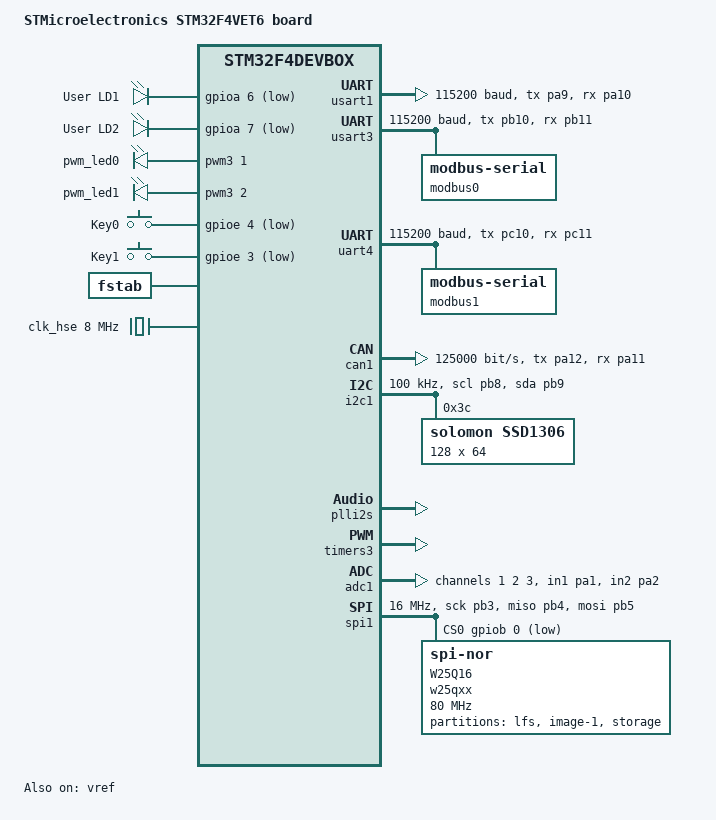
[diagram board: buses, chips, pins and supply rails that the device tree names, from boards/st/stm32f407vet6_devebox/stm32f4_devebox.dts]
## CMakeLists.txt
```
# SPDX-License-Identifier: Apache-2.0

cmake_minimum_required(VERSION 3.20.0)
list(APPEND BOARD_ROOT ${CMAKE_CURRENT_SOURCE_DIR}) # 添加当前目录到BOARD_ROOT
find_package(Zephyr REQUIRED HINTS $ENV{ZEPHYR_BASE})
project(blinky_test)

target_include_directories(app PRIVATE src)
target_include_directories(app PRIVATE src/driver)
target_include_directories(app PRIVATE src/modbus)


target_sources(app PRIVATE src/main.c)

target_sources(app PRIVATE src/driver/adc.c)
target_sources(app PRIVATE src/driver/can_driver.c)
target_sources(app PRIVATE src/driver/fs_storage.c)
target_sources(app PRIVATE src/driver/iic_board.c)
target_sources(app PRIVATE src/driver/modbus_driver.c)
target_sources(app PRIVATE src/driver/uart.c)
target_sources(app PRIVATE src/driver/w25qxx.c)

target_sources(app PRIVATE src/modbus/modbus_ser_a.c)
target_sources(app PRIVATE src/modbus/modbus_cli_a.c)

target_sources(app PRIVATE src/gpio-ctr.c)
target_sources(app PRIVATE src/sys_param.c)
target_sources(app PRIVATE src/oled1306.c)
```

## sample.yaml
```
sample:
  name: Blinky Sample test
tests:
  sample.basic.blinky:
    tags:
      - LED
      - gpio
    filter: dt_enabled_alias_with_parent_compat("led0", "gpio-leds")
    depends_on: gpio
    harness: led
    integration_platforms:
      - frdm_k64f
```

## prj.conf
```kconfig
# =============================================================================
# 调试编译相关配置
# =============================================================================
# CONFIG_DEBUG: 启用调试符号（-g 编译选项）
# 这是所有调试功能的前提，不启用则 GDB 无法映射源码与机器码
CONFIG_DEBUG=y
# 编译优化等级（四选一，互斥）:
#   CONFIG_NO_OPTIMIZATIONS=y   → -O0  零优化，GDB完美调试，代码体积最大
#   CONFIG_DEBUG_OPTIMIZATIONS=y → -Og  调试优化甜点，GDB基本可用，体积比-O0小30-40%
#   （都不设，默认）             → -O2  速度优化，GDB变量常"optimized out"
#   CONFIG_SIZE_OPTIMIZATIONS=y → -Os  体积最小，GDB体验差
# 推荐：日常开发用 -Og（调试与空间的甜点），发布用 -Os
CONFIG_DEBUG_OPTIMIZATIONS=y
# CONFIG_DEBUG_THREAD_INFO: 生成 _kernel_thread_info_offsets 符号
# 原因：OpenOCD 的 Zephyr RTOS 线程感知插件依赖此符号
#       不启用则 OpenOCD 持续报错 "offsets not found"，并可能导致断点失效
#       报错示例："can't find _kernel_thread_info_offsets in symbol table"
CONFIG_DEBUG_THREAD_INFO=y


# =============================================================================
# 线程与日志等配置
# =============================================================================
# CONFIG_THREAD_STACK_INFO: 在线程信息中包含栈指针和栈大小
# GDB/OpenOCD 线程感知需要，用于显示每个线程的栈使用情况
CONFIG_THREAD_STACK_INFO=y
# CONFIG_THREAD_MONITOR: 启用线程监控链表
# OpenOCD 通过遍历内核线程链表枚举所有线程
CONFIG_THREAD_MONITOR=y
# CONFIG_THREAD_NAME: 允许为线程设置名称
# GDB 中显示线程名而非编号，便于识别（如 "main", "idle"）
CONFIG_THREAD_NAME=y

# CONFIG_LOG: 启用 Zephyr 日志子系统
CONFIG_LOG=y
#增大日志缓冲区（默认1024字节，参数系统初始化时日志密集会导致丢消息）
CONFIG_LOG_BUFFER_SIZE=4096

# 启用 Zephyr Shell 子系统
CONFIG_SHELL=y



# =============================================================================
# 修改默认堆栈
# =============================================================================
# 系统工作队列栈大小 (默认 1024)
CONFIG_SYSTEM_WORKQUEUE_STACK_SIZE=4096
#修改主线程栈大小，不开就是默认值
CONFIG_MAIN_STACK_SIZE=4096


# =============================================================================
# MCUboot 配置
# =============================================================================
#启动MCUboot
CONFIG_BOOTLOADER_MCUBOOT=y
# 签名密钥 — 使用 MCUboot 自带的 RSA-2048 默认开发密钥
# 生产环境必须替换为自己的密钥对
CONFIG_MCUBOOT_SIGNATURE_KEY_FILE="bootloader/mcuboot/root-rsa-2048.pem"
# 必须与 MCUboot 的配置保持一致！否则 flash_img 写入偏移与 MCUboot 读取偏移不匹配
# MCUboot 配置了 BOOT_UPGRADE_ONLY=y，APP 也必须使用 OVERWRITE_ONLY 模式
CONFIG_MCUBOOT_BOOTLOADER_MODE_OVERWRITE_ONLY=y

# SPI NOR 页大小等配置已移至 MCUboot 板级配置文件:
#   bootloader/mcuboot/boot/zephyr/boards/stm32f4_devebox.conf
# # Overwrite 模式CONFIG_BOOT_UPGRADE_ONLY=y  Flash 页大小CONFIG_SPI_NOR_FLASH_LAYOUT_PAGE_SIZE=4096
# # 镜像最大扇区数CONFIG_BOOT_MAX_IMG_SECTORS_AUTO=n  CONFIG_BOOT_MAX_IMG_SECTORS=256


# =============================================================================
# MCUmgr DFU 升级配置
# =============================================================================
# MCUmgr 依赖项（Kconfig 不会自动启用，需显式声明）
CONFIG_ZCBOR=y
CONFIG_NET_BUF=y
CONFIG_BASE64=y

# MCUmgr 核心开关
CONFIG_MCUMGR=y
# Image 管理组：提供固件上传、查询、标记升级等命令
CONFIG_MCUMGR_GRP_IMG=y
# DFU 镜像管理器（MCUMGR_GRP_IMG 的依赖，需显式启用）
CONFIG_IMG_MANAGER=y
# OS 管理组：提供远程复位命令（升级后重启进入 MCUboot 执行升级）
CONFIG_MCUMGR_GRP_OS=y
# 流式写入 Flash（MCUmgr 上传固件时需要）
CONFIG_STREAM_FLASH=y
# 允许直接上传到指定 slot（不强制从 slot0 开始）
CONFIG_MCUMGR_GRP_IMG_DIRECT_UPLOAD=y

# Shell 传输：复用现有 Shell 串口进行 SMP 通信
# 优点：无需额外 UART，同一串口同时支持 Shell 命令和 MCUmgr DFU
CONFIG_MCUMGR_TRANSPORT_SHELL=y
# Shell 传输 MTU（默认 256，增大可提升上传速度）
CONFIG_MCUMGR_TRANSPORT_SHELL_MTU=512
# MCUmgr 网络缓冲区大小（默认 384，DFU 场景需增大）
CONFIG_MCUMGR_TRANSPORT_NETBUF_SIZE=2048

# 调试: 启用 MCUMGR 和 stream_flash DEBUG 日志，排查上传失败原因
CONFIG_MCUMGR_LOG_LEVEL_DBG=y
CONFIG_STREAM_FLASH_LOG_LEVEL_DBG=y
CONFIG_IMG_MANAGER_LOG_LEVEL_DBG=y





#GPIO子系统
CONFIG_GPIO=y
#启用输入子系统
CONFIG_INPUT=y
#GPIO按键输入驱动 (gpio-keys compatible 节点的驱动)
#当 DTS 中存在 compatible = "gpio-keys" 节点时，此选项默认启用 (default y)
#显式声明以便于理解配置意图
CONFIG_INPUT_GPIO_KEYS=y
#启用PWM子系统
CONFIG_PWM=y

#启用ADC子系统
CONFIG_ADC=y
#启用ADC调试日志
#CONFIG_ADC_LOG_LEVEL_DBG=y

#启用DMA子系统
CONFIG_DMA=y
# ADC DMA 模式（依赖 DMA 子系统 + DTS 中 ADC 节点已启用）
CONFIG_ADC_STM32_DMA=y
#关闭DMA模块日志输出
#原因：STM32F4 的 DMA V1 驱动对 burst_length 的处理存在语义不匹配——
#  Zephyr API 定义 burst_length 单位为字节，ADC 驱动设置 burst_length=2（16位数据），
#  但 DMA V1 驱动将其当作 beat 数匹配，只接受 {1,4,8,16}，导致每次 ADC DMA 读取时
#  产生 "Peripheral/Memory burst size error" 的 LOG_ERR 误报。
#  实际功能不受影响（驱动自动回退到 single burst），但 ERR 级别日志会污染日志系统。
#排查DMA问题时，可改用 CONFIG_DMA_LOG_LEVEL_ERR 或 CONFIG_DMA_LOG_LEVEL_DBG 重新开启
CONFIG_DMA_LOG_LEVEL_OFF=y

#启用UART子系统
CONFIG_SERIAL=y
#启用UART中断驱动 (uart_irq_rx_enable / uart_irq_callback_set 等 API 的开关)
#不开启的话中断 API 不会被编译进驱动, 中断永不触发
CONFIG_UART_INTERRUPT_DRIVEN=y
#启用UART异步API (uart_tx / uart_rx_enable / uart_callback_set)
#依赖 DMA, 需要 DTS 中配置 dmas 属性
CONFIG_UART_ASYNC_API=y

#启用Modbus子系统
CONFIG_MODBUS=y
#启用Modbus客户端+服务端 (Kconfig choice三选一: CLIENT / SERVER / CLIENT_SERVER)
CONFIG_MODBUS_ROLE_CLIENT_SERVER=y


# 启用 CAN 子系统（CAN 驱动框架核心）
CONFIG_CAN=y
# CAN Shell 命令（调试用，可通过 shell 测试 CAN 收发）
# 命令: can send/can start/can stop/can state 等
CONFIG_CAN_SHELL=y
# CAN 总线状态统计（can_stats_get_bit_errors 等 API 依赖）
# 调试时建议启用，正式发布可关闭
# 需要先启用 STATS 模块
CONFIG_STATS=y
CONFIG_CAN_STATS=y
# CAN 驱动日志级别（调试用，可看到 MCP2515 底层收发日志）
# 正式发布时改为 _WRN 或关闭
# CONFIG_CAN_LOG_LEVEL_DBG=y
CONFIG_CAN_LOG_LEVEL_INF=y


#启用I2C子系统
CONFIG_I2C=y
#启用I2C Shell命令（调试用，可通过shell扫描总线、读写寄存器）
#用法: i2c scan I2C_1          — 扫描总线上所有设备
#      i2c read_byte I2C_1 0x3C 0x00  — 从地址0x3C的设备读寄存器0x00
#CONFIG_I2C_SHELL=y

#启用Display子系统（OLED SSD1306 驱动依赖）
CONFIG_DISPLAY=y
#启用SSD1306驱动（当DTS中存在 compatible="solomon,ssd1306" 节点时默认自动启用）
#显式声明以便于理解配置意图
CONFIG_SSD1306=y




#启用SPI子系统（SPI控制器驱动依赖）
CONFIG_SPI=y
#启用Flash子系统（jedec,spi-nor驱动依赖）
#CONFIG_SPI_NOR 不需要手动开启，当DTS中存在 compatible="jedec,spi-nor" 节点时自动启用
CONFIG_FLASH=y
#启用Flash页面布局信息（flash_get_page_info_by_offs 等API依赖）
CONFIG_FLASH_PAGE_LAYOUT=y
# SPI NOR Flash 页大小（最小擦除单位）
# W25Q16 最小擦除单位是 4KB，必须设置为此值
# 默认值 65536 (64KB) 会导致 MCUboot boot_slots_compatible() 检查失败
# 同时也影响 LittleFS 的块大小选择，4KB 更精确
CONFIG_SPI_NOR_FLASH_LAYOUT_PAGE_SIZE=4096

#启用文件系统子系统（VFS核心层）
CONFIG_FILE_SYSTEM=y
#启用LittleFS文件系统（嵌入式首选，掉电安全+磨损均衡）
CONFIG_FILE_SYSTEM_LITTLEFS=y
#启用Flash Map API（LittleFS通过flash_area读写底层Flash分区）
CONFIG_FLASH_MAP=y
#启用fstab自动挂载（DTS中设置automount的条目在SYS_INIT阶段自动挂载）
CONFIG_FS_LITTLEFS_FSTAB_AUTOMOUNT=y
#启用Flash Shell命令（调试用，可通过shell查看分区和Flash信息）
CONFIG_FLASH_SHELL=y

#启用Settings子系统（参数持久化存储框架）
CONFIG_SETTINGS=y
#使用File后端（基于LittleFS文件系统存储Settings键值对）
CONFIG_SETTINGS_FILE=y
#Settings文件存储路径（必须在已挂载的LittleFS挂载点下）
CONFIG_SETTINGS_FILE_PATH="/lfs1/settings/run"
#Settings文件最大行数（超过后自动压缩去重，减少Flash占用）
CONFIG_SETTINGS_FILE_MAX_LINES=32
```

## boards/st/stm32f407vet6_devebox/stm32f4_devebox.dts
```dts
/*
 * Copyright (c) 2017 Linaro Limited
 *
 * SPDX-License-Identifier: Apache-2.0
 */

/dts-v1/;
#include <st/f4/stm32f407Xg.dtsi>
#include <st/f4/stm32f407v(e-g)tx-pinctrl.dtsi>
#include <zephyr/dt-bindings/input/input-event-codes.h>
#include <zephyr/dt-bindings/dma/stm32_dma.h>

/ {
	model = "STMicroelectronics STM32F4VET6 board";
	compatible = "st,stm32f4devbox";

	/*
	 * chosen 节点: Zephyr 系统的运行时配置参数
	 *
	 * Q: 最少需要指定哪些参数？
	 *
	 * A: 严格来说没有"最少"，但一个能正常启动的 Zephyr 应用至少需要:
	 *    zephyr,sram  — 告诉内核 SRAM 的起始地址和大小（用于内存管理）
	 *    zephyr,flash — 告诉内核 Flash 的起始地址和大小（用于代码定位）
	 *
	 *    zephyr,console  是可选的，但没它就没有串口输出。
	 *    zephyr,shell-uart 也是可选的，只有用 shell 子系统时才需要。
	 *
	 *    常用 chosen 属性一览:
	 *    zephyr,sram        — RAM 节点，内核堆和线程栈从这里分配
	 *    zephyr,flash       — Flash 节点，代码和只读数据存放位置
	 *    zephyr,console     — 默认控制台设备（printk 输出目标）
	 *    zephyr,shell-uart  — Shell 子系统使用的 UART
	 *    zephyr,uart-pipe   — 远程 shell 管道用的 UART
	 *    zephyr,code-partition  — 代码烧录的分区
	 *    zephyr,dtcm / zephyr,itcm — TCM 内存（Cortex-M7 等）
	 */
	chosen {
		zephyr,console = &usart1;
		zephyr,shell-uart = &usart1;
		zephyr,sram = &sram0;
		zephyr,flash = &flash0;
		zephyr,code-partition = &slot0_partition;//指定代码烧录的分区
		zephyr,display = &ssd1306;               //默认显示设备（Display API / LVGL 使用）
	};

	leds {
		compatible = "gpio-leds";

		/*
		 * 设备树节点定义语法:  label: node-name { ... };
		 *
		 *   label     (冒号左边): 节点标签，用于被 & 引用，如 &led0
		 *   node-name (冒号右边): 节点名称，是节点在设备树路径中的名称
		 *
		 * 【易错点】aliases 中 & 引用的是 label，不是 node-name！
		 *
		 *   正确: led0: led_0 { ... };  aliases { led0 = &led0; }
		 *   错误: led0: led_0 { ... };  aliases { led0 = &led_0; }  ← 编译报错！
		 *
		 * 因为 &led_0 试图引用名为 "led_0" 的标签，但标签是 "led0"。
		 * 报错信息: "devicetree error: /aliases: undefined node label 'led_0'"
		 *
		 * 【推荐写法】为避免混淆，建议 label 和 node-name 使用不同命名：
		 *   green_led: led_0 { ... };   aliases { led0 = &green_led; }
		 *   参考 stm32f4_disco 板卡的写法。
		 */
		led0: led_0 {
			gpios = <&gpioa 6 GPIO_ACTIVE_LOW>;
			label = "User LD1";
		};

		led1: led_1 {
			gpios = <&gpioa 7 GPIO_ACTIVE_LOW>;
			label = "User LD2";
		};
	};

	pwmleds: pwmleds {
		compatible = "pwm-leds";

		pwm_led0: pwm_led_0 {
		pwms = <&pwm3 1 PWM_MSEC(20) PWM_POLARITY_NORMAL>;
		/* &pwm3: 引用 timers3 的 pwm 子节点 */
		/* 1: TIM3 通道 1 → PA6 */
		/* PWM_MSEC(20): 周期 20ms = 50Hz，适合 LED 调光 */
		};

		pwm_led1: pwm_led_1 {
		pwms = <&pwm3 2 PWM_MSEC(20) PWM_POLARITY_NORMAL>;
		/* 2: TIM3 通道 2 → PA7 */
		};
	};

	gpio_keys: gpio_keys {
		compatible = "gpio-keys";
		debounce-interval-ms = <30>;    /* 去抖时间 30ms */
		user_button0: button0 {
			label = "Key0";
			gpios = <&gpioe 4 GPIO_ACTIVE_LOW>;
			zephyr,code = <INPUT_KEY_0>;
		};

		user_button1: button1 {
			label = "Key1";
			gpios = <&gpioe 3 GPIO_ACTIVE_LOW>;
			zephyr,code = <INPUT_KEY_1>;
		};

	};

	longpress: longpress {
		compatible = "zephyr,input-longpress";
		input = <&gpio_keys>;                              /* 监听哪个设备，不填则监听所有 */
		input-codes = <INPUT_KEY_0>, <INPUT_KEY_1>;        /* 要检测的按键码 */
		short-codes = <INPUT_KEY_A>, <INPUT_KEY_B>;        /* 短按时输出的码 */
		long-codes = <INPUT_KEY_X>, <INPUT_KEY_Y>;         /* 长按时输出的码 */
		long-delay-ms = <2000>;                             /* 超过此时间算长按 */
	};

	/*
	 * aliases 节点: 为节点创建别名，供 C 代码通过 DT_ALIAS() 宏引用。
	 *
	 * 例如: #define LED0_NODE DT_ALIAS(led0)
	 *       会解析到 aliases 中的 led0 = &led0，进而找到 leds/led_0 节点。
	 *
	 * Zephyr 常用别名约定:
	 *   led0, led1, led2, ...   → LED 指示灯
	 *   sw0, sw1, sw2, ...      → 按键开关
	 *   bt0, bt1, ...           → 按键（另一种命名）
	 *   volt-sensor0, ...       → 电压传感器
	 *   die-temp0, ...          → 芯片温度传感器
	 */
	aliases {
		led0 = &led0;
		led1 = &led1;
		pwm-led0 = &pwm_led0;
		pwm-led1 = &pwm_led1;
		bt0 = &user_button0;
		bt1 = &user_button1;
		adc1 = &adc1;
		volt-sensor0 = &vref;
	};
};


&flash0 {
	partitions {
		compatible = "fixed-partitions";
		#address-cells = <1>;
		#size-cells = <1>;

		/*
		 * STM32F407VET6 内部 flash: 512KB
		 *
		 * 扇区布局（最小擦除单位 = 整个扇区）:
		 * Sector 0: 0x00000000, 16KB
		 * Sector 1: 0x00004000, 16KB
		 * Sector 2: 0x00008000, 16KB
		 * Sector 3: 0x0000C000, 16KB
		 * Sector 4: 0x00010000, 64KB
		 * Sector 5: 0x00020000, 128KB
		 * Sector 6: 0x00040000, 128KB
		 * Sector 7: 0x00060000, 128KB
		 *
		 * MCUboot 分区规划（Overwrite 模式 + 外部 flash slot1）:
		 *   mcuboot  : 48KB   — 引导加载程序（Sector 0~2）
		 *   image-0  : 464KB  — 主应用固件（Sector 3~7）
		 *   image-1  : 512KB  — 升级固件暂存（W25Q16 外部 flash）
		 *
		 * Overwrite 模式说明:
		 *   升级时 MCUboot 从外部 flash 的 slot1 读取镜像，
		 *   覆写到内部 flash 的 slot0，无需 scratch 分区。
		 *   优点: 内部 flash 空间最大化（464KB vs 旧方案 208KB）
		 *   缺点: 升级中断无法回滚（需确保升级过程完整）
		 *   配置: MCUboot 需启用 CONFIG_BOOT_UPGRADE_ONLY=y
		 *
		 * 跨设备 flash 工作原理:
		 *   Zephyr flash_map 为每个分区生成 flash_area 结构体，
		 *   其中 fa_dev 指向对应的 flash 驱动设备:
		 *     slot0 (内部 flash) → fa_dev = SOC_FLASH_STM32 驱动
		 *     slot1 (W25Q16)     → fa_dev = SPI_NOR 驱动
		 *   MCUboot 的 flash_area_read/write/erase 通过 fa_dev
		 *   自动路由到正确的驱动，无需手动区分设备。
		 *
		 *   Overwrite 模式关键路径:
		 *     1. boot_read_image_headers() → flash_area_read(slot1) → SPI NOR 驱动
		 *     2. bootutil_img_validate()   → flash_area_read(slot1) → SPI NOR 驱动
		 *     3. boot_copy_region()        → read(slot1) + write(slot0) → 跨设备复制
		 *     4. do_boot()                 → flash_device_base(slot0) → 内部 flash 跳转
		 *   所有 I/O 操作通过 fa_dev 路由，跳转地址始终是内部 flash。
		 *
		 * 必要配置:
		 *   1. CONFIG_SPI_NOR_FLASH_LAYOUT_PAGE_SIZE=4096
		 *      W25Q16 最小擦除单位是 4KB，必须让驱动报告真实值，
		 *      否则 boot_slots_compatible() 会因 64KB 不能整除 16KB 而失败
		 *   2. CONFIG_BOOT_MAX_IMG_SECTORS=256
		 *      slot1 有 512KB/4KB = 128 个扇区，需增大默认值
		 *
		 * MCUboot 编译命令:
		 *   zephyrproject\bootloader\mcuboot\boot\zephyr> \
		 *   west build -b stm32f4_devebox -d build_mcuboot -- \
		 *     -DCONFIG_BOOT_UPGRADE_ONLY=y
		 *   板级配置文件 boards/stm32f4_devebox.conf 会自动加载
		 */

		boot_partition: partition@0 {
			label = "mcuboot";
			reg = <0x00000000 DT_SIZE_K(48)>;
			read-only;
		};
		slot0_partition: partition@c000 {
			label = "image-0";
			reg = <0x0000C000 DT_SIZE_K(464)>;
		};
	};
};


/*
 * DMA1 必须启用，因为 UART3 和 UART4 的 DMA 请求连接在 DMA1 上：
 *   UART3_TX → DMA1 Stream3 Ch4    UART3_RX → DMA1 Stream1 Ch4
 *   UART4_TX → DMA1 Stream4 Ch4    UART4_RX → DMA1 Stream2 Ch4
 */
&dma1 {
	status = "okay";
};

&dma2 {
	status = "okay";
};

&clk_lsi {
	status = "okay";
};

&clk_hse {
	clock-frequency = <DT_FREQ_M(8)>;
	status = "okay";
};

&pll {
	div-m = <8>;
	mul-n = <336>;
	div-p = <2>;
	div-q = <7>;
	clocks = <&clk_hse>;
	status = "okay";
};

&rcc {
	clocks = <&pll>;
	clock-frequency = <DT_FREQ_M(168)>;
	ahb-prescaler = <1>;
	apb1-prescaler = <4>;
	apb2-prescaler = <2>;
};

&usart1 {
	pinctrl-0 = <&usart1_tx_pa9 &usart1_rx_pa10>;
	pinctrl-names = "default";
	current-speed = <115200>;
	status = "okay";
};

&usart3 {
	pinctrl-0 = <&usart3_tx_pb10 &usart3_rx_pb11>;
	pinctrl-names = "default";
	current-speed = <115200>;
	/*
	 * Async API (DMA 模式) 需要 dmas:
	 *   3 = DMA1 Stream 3 (TX),   4 = Channel 4 (USART3_TX 请求线)
	 *   1 = DMA1 Stream 1 (RX),   4 = Channel 4 (USART3_RX 请求线)
	 *   STM32_DMA_PERIPH_TX = MEM_TO_PERIPH | MEM_INC (默认 8-bit)
	 *   STM32_DMA_PERIPH_RX = PERIPH_TO_MEM | MEM_INC (默认 8-bit)
	 */
	dmas = <&dma1 3 4 STM32_DMA_PERIPH_TX STM32_DMA_FIFO_FULL>,
	       <&dma1 1 4 STM32_DMA_PERIPH_RX STM32_DMA_FIFO_FULL>;
	dma-names = "tx", "rx";
	status = "okay";

	modbus0 {
		compatible = "zephyr,modbus-serial";
		status = "okay";
		/* RS485 收发器需配置 DE 引脚，TTL 直连可省略 */
		/* de-gpios = <&gpiox pin GPIO_ACTIVE_HIGH>; */
	};
};

&uart4 {
	pinctrl-0 = <&uart4_tx_pc10 &uart4_rx_pc11>;
	pinctrl-names = "default";
	current-speed = <115200>;
	/*
	 * UART4 的 DMA 通道:
	 *   4 = DMA1 Stream 4 (TX),   4 = Channel 4 (UART4_TX 请求线)
	 *   2 = DMA1 Stream 2 (RX),   4 = Channel 4 (UART4_RX 请求线)
	 */
	dmas = <&dma1 4 4 STM32_DMA_PERIPH_TX STM32_DMA_FIFO_FULL>,
	       <&dma1 2 4 STM32_DMA_PERIPH_RX STM32_DMA_FIFO_FULL>;
	dma-names = "tx", "rx";
	status = "okay";
	modbus1 {
		compatible = "zephyr,modbus-serial";
		status = "okay";
		/* RS485 收发器需配置 DE 引脚，TTL 直连可省略 */
		/* de-gpios = <&gpiox pin GPIO_ACTIVE_HIGH>; */
	};
};

&can1 {
	pinctrl-0 = <&can1_tx_pa12 &can1_rx_pa11>;
	pinctrl-names = "default";
	bitrate = <125000>;
	sample-point = <875>;
	status = "okay";

	can-transceiver {
		max-bitrate = <1000000>;
	};
};

/*
 * I2C1 节点配置详解
 *
 * Q: pinctrl-0 和 pinctrl-names 是什么？为什么 I2C 必须配置？
 *
 * A: pinctrl (Pin Controller) 是 Zephyr 的引脚复用配置机制。
 *    STM32 的每个引脚可以映射到多种外设功能（AF），必须显式指定。
 *
 *    pinctrl-0: 引用 pinctrl dtsi 中预定义的引脚配置节点
 *    pinctrl-names: 为 pinctrl-0 起个名字，"default" 表示默认（也是唯一）配置
 *
 *    I2C 引脚必须配置的原因:
 *    1. STM32 引脚默认是 GPIO 模式，不配置 pinctrl 则 I2C 信号无法输出到引脚
 *    2. I2C 是开漏协议，必须设置 drive-open-drain（pinctrl dtsi 中已预设）
 *    3. I2C 需要上拉电阻，pinctrl 中已设置 bias-pull-up（内部弱上拉，外部仍需上拉）
 *
 *    PB8 = I2C1_SCL (AF4), PB9 = I2C1_SDA (AF4)
 *    这是 I2C1 的默认引脚，定义在 stm32f407v(e-g)tx-pinctrl.dtsi 中
 *
 * Q: clock-frequency 的选择？
 *
 * A: I2C 标准定义了三种速率:
 *    I2C_BITRATE_STANDARD = 100 KHz  (标准模式, 默认值, 兼容性最好)
 *    I2C_BITRATE_FAST     = 400 KHz  (快速模式, 大多数传感器支持)
 *    I2C_BITRATE_FAST_PLUS = 1 MHz   (高速模式, 部分设备支持)
 *
 *    注意: 速率越高，信号完整性要求越高，线长越短。
 *    面包板/杜邦线建议用 100KHz，PCB 短线可用 400KHz。
 *
 * Q: 总线上的设备子节点怎么写？
 *
 * A: I2C 总线设备子节点格式:
 *    device_name: device@address {
 *        compatible = "vendor,device";   // 匹配驱动
 *        reg = <address>;               // 7位地址（不含R/W位）
 *        label = "Friendly Name";       // 旧式标签（可选）
 *    };
 *
 *    address 是 7 位地址（0x00~0x7F），不含最低位的 R/W 标志。
 *    例如: 0x78 = 0b01111000，这是 7 位地址 0x3C 左移 1 位的结果
 *    如果设备数据手册写的是 8 位地址 0x78，则 7 位地址 = 0x78 >> 1 = 0x3C
 *
 *    【重要】0x78 的两种解读:
 *    - 如果 0x78 是 8 位写地址（最常见）: 7 位地址 = 0x78 >> 1 = 0x3C
 *    - 如果 0x78 已经是 7 位地址（少见）: reg = <0x78>
 *    大多数 I2C 设备数据手册给出的地址是包含 R/W 位的 8 位格式，
 *    OLED SSD1306 的常见地址就是 0x3C（7位）或 0x78（8位写）。
 */
&i2c1 {
	pinctrl-0 = <&i2c1_scl_pb8 &i2c1_sda_pb9>;
	pinctrl-names = "default";
	clock-frequency = <I2C_BITRATE_STANDARD>;
	status = "okay";

	/*
	 * SSD1306 OLED 显示屏 (128x64, I2C)
	 *
	 * compatible: "solomon,ssd1306" — 匹配 Zephyr 内置的 SSD1306 驱动
	 *   驱动源码: zephyr/drivers/display/display_ssd1306.c
	 *   DTS绑定: zephyr/dts/bindings/display/solomon,ssd1306-common.yaml
	 *
	 * 属性说明:
	 *   reg              — 7 位 I2C 地址 (0x3C = 8位地址 0x78 >> 1)
	 *   width/height     — 显示分辨率（像素）
	 *   segment-offset   — 列起始偏移（Page 寻址模式下，0 表示从第 0 列开始）
	 *   page-offset      — 页起始偏移（0 表示从第 0 页开始）
	 *   display-offset   — 显示 RAM 到屏幕的行偏移（0 表示无偏移）
	 *   multiplex-ratio  — 复用比 = height - 1（128x64 → 63, 128x32 → 31）
	 *   prechargep       — 预充电周期 [高位:Phase2 低位:Phase1]，0x22 为典型值
	 *   segment-remap    — 水平镜像（列地址 127 映射到 SEG0）
	 *   com-invdir       — 垂直镜像（COM 扫描方向从 COM63 到 COM0）
	 *
	 * segment-remap + com-invdir 的组合效果:
	 *   都不设: 正常方向（适合大多数模块的默认方向）
	 *   都设置: 旋转 180°（如果显示内容上下颠倒，加这两个属性）
	 *   只设一个: 水平或垂直镜像
	 *
	 * reset-gpios: 可选，硬件 RESET 引脚。如果你的模块没有连接 RESET 引脚
	 *   （很多廉价模块直接把 RESET 拉高），可以省略此属性。
	 *   驱动会使用软件复位命令代替。
	 *
	 * SSD1315 兼容性说明:
	 *   SSD1315 是 SSD1306 的国产替代芯片，指令集高度兼容。
	 *   大多数情况下 "solomon,ssd1306" 驱动可以直接驱动 SSD1315。
	 *   如果显示异常，可能需要调整 prechargep 或对比度参数。
	 */
	ssd1306: ssd1306@3c {
		compatible = "solomon,ssd1306";
		reg = <0x3c>;
		width = <128>;
		height = <64>;
		segment-offset = <0>;
		page-offset = <0>;
		display-offset = <0>;
		multiplex-ratio = <63>;
		prechargep = <0x22>;
		segment-remap;
		com-invdir;
	};

	/*
	 * 通用 I2C 设备节点（保留用于 I2C 底层学习）
	 *
	 * 这个节点使用 "zephyr,i2c-device" 通用 compatible，不绑定任何专用驱动。
	 * iic_board.c 中的 i2c_board_scan()、i2c_board_write_reg() 等底层 API
	 * 使用此节点的地址进行 I2C 总线操作练习。
	 *
	 * 注意: SSD1306 和此节点共享同一个 I2C 地址 0x3C，它们是同一个物理设备。
	 *   - 使用 Zephyr Display API 操作屏幕时，通过 ssd1306 节点
	 *   - 学习 I2C 底层通信时，通过此节点（i2c_board_test 等）
	 *   两者不要同时操作，否则可能产生总线冲突。
	 */
	i2c_device_0x78: i2cdev@3c {
		compatible = "zephyr,i2c-device";
		reg = <0x3C>;
		label = "I2C_DEV_0x78";
		/*
		 * 默认禁用: 与 ssd1306 节点共享同一 I2C 地址 0x3C。
		 * 启用 SSD1306 驱动时，两个节点同时 enabled 会导致驱动冲突。
		 * 使用 iic_board 底层测试时，需要:
		 *   1. 将此节点改为 status = "okay"
		 *   2. 将 ssd1306 节点改为 status = "disabled"
		 *   3. 重新编译
		 */
		status = "disabled";
	};
};

/*
 * &vref: 内部参考电压（VREFINT）监测器
 *
 * Q: 这个是什么？一定需要 okay 吗？
 *
 * A: vref 是 STM32 芯片内部的一个校准电压通道（ADC1 通道 17），
 *    电压约 1.21V 且非常稳定。它不是外部引脚，而是芯片内部连接到
 *    ADC 的专用信号。
 *
 *    用途:
 *    1. adc_raw_to_millivolts() 内部用 vref 的值来计算实际 VDDA
 *       因为 VDDA 不一定是精确的 3.3V（可能是 3.2~3.4V），通过
 *       测量稳定的 VREFINT 可以反推真实的 VDDA 电压。
 *
 *       VDDA_real = VREFINT_cal / VREFINT_measured × VDDA_cal
 *       (VREFINT_cal 出厂时校准值存储在 Flash OTP 区域)
 *
 *    2. 如果不启用 vref，adc_raw_to_millivolts() 假定 VDDA = 3.3V
 *       精度会下降，但对于学习项目差异不大。
 *
 *    结论: 学习阶段不启用也可以（status = "disabled"），
 *          但启用后 ADC 电压转换更精确。
 */
&vref {
	status = "okay";
};


&plli2s {
	/* Minimize audio clock error (with i2s mck-enabled) for all of:
	 * - 22.05kHz / 16b, 24b or 32b
	 * - 44.1kHz  / 16b, 24b or 32b
	 * - 88.2kHz  / 16b or 24b
	 * Note: because the PLLI2S is dependent on the main PLL, the latter
	 *       should not be changed without checking impact on PLLI2S
	 */
	div-m = <8>;
	mul-n = <271>;
	div-r = <2>;
	clocks = <&clk_hse>;
	status = "okay";
};

&timers3 {
    status = "okay";
    st,prescaler = <83>;

    pwm3: pwm {
        status = "okay";
        pinctrl-0 = <&tim3_ch1_pa6 &tim3_ch2_pa7>;
        pinctrl-names = "default";
    };
};

/*
 * ============================================================================
 * ADC1 节点配置详解
 * ============================================================================
 *
 * Q: #address-cells = <1>  这是什么？为什么是 1？
 *
 * A: #address-cells 指定子节点 reg 属性中"地址"部分占用的 cell 数量。
 *    一个 cell 是 32 位整数。
 *
 *    #address-cells = <1> 意味着子节点的 reg = <地址>，只占 1 个 cell。
 *    例如: channel@1 { reg = <1>; }  — 1 cell 的地址
 *
 *    如果是 #address-cells = <2>，则需要 2 个 cell:
 *        somechild@1000,2000 { reg = <0x1000 0x2000>; }
 *
 *    常见值:
 *    <1> 用于简单索引地址（通道号、端口号等）
 *    <2> 用于 64 位地址（如 32 位处理器的 64 位外设地址）
 *
 * Q: #size-cells = <0>  这是什么？为什么是 0？
 *
 * A: #size-cells 指定子节点 reg 属性中"大小"部分占用的 cell 数量。
 *
 *    #size-cells = <0> 意味着子节点的 reg 只有"地址"没有"大小"。
 *    channel@1 { reg = <1>; }     — 只有地址 1，无大小
 *
 *    #size-cells = <1>:
 *    somenode@40000000 { reg = <0x40000000 0x400>; }  — 地址 + 大小
 *
 *    对于 ADC 通道，通道号 (1, 2, ...) 本身就是地址，没有"大小"概念，
 *    所以 #size-cells = <0>。
 *
 * Q: dmas = <&dma2 0 0 (STM32_DMA_PERIPH_RX | STM32_DMA_16BITS) STM32_DMA_FIFO_FULL>;
 *    定义了 dmas 可以不使用 dma 吗？参数什么含义？
 *
 * A: 可以！dmas 只是声明"我可以用 DMA"，是否实际启用取决于:
 *    - Kconfig: CONFIG_DMA=y 且 CONFIG_ADC_STM32_DMA=y
 *    - DTS: dma 控制器本身 status = "okay"
 *    如果 Kconfig 没开，dmas 属性被编译进 DT 但驱动不会初始化 DMA。
 *
 *    4 个 cell 参数的含义 (st,stm32-dma-v1 的 #dma-cells = <4>):
 *
 *    Cell 0 (channel): 0  — DMA2 的流编号 (Stream 0)
 *         STM32F4 有 2 个 DMA 控制器，每个 8 个 Stream (0~7)。
 *         ADC1 可以使用 DMA2 Stream 0 或 Stream 4，这里选 Stream 0。
 *
 *    Cell 1 (slot):    0  — DMA 请求通道号 (Channel 0)
 *         每个外设在 DMA 控制器上有一个固定的请求通道。
 *         STM32F407 中 ADC1 的 DMA 请求连接到 DMA2 Channel 0。
 *
 *    Cell 2 (channel_config): (STM32_DMA_PERIPH_RX | STM32_DMA_16BITS)
 *         STM32_DMA_PERIPH_RX = PERIPH_TO_MEMORY(方向:外设→内存) | MEM_INC(内存地址递增)
 *         STM32_DMA_16BITS    = PERIPH_16BITS(外设数据16位宽) | MEM_16BITS(内存数据16位宽)
 *         两者按位或组合成完整的通道配置位域。
 *
 *    Cell 3 (features): STM32_DMA_FIFO_FULL — FIFO 阈值全满
 *         FIFO_THRESHOLD_1_4 = 0  (1/4 满触发传输)
 *         FIFO_THRESHOLD_HALF = 1 (半满触发传输)
 *         FIFO_THRESHOLD_3_4  = 2 (3/4 满触发传输)
 *         FIFO_THRESHOLD_FULL = 3 (全满触发传输)
 *         对于 ADC DMA，这个值影响不大，驱动会自动处理。
 *
 * Q: channel@1 中四个参数什么意思？和 adc.c 重复吗？
 *
 * A: DTS 中的属性声明硬件默认值，C 代码中的 adc_channel_cfg 是运行时配置。
 *
 *    两者关系:
 *    DTS channel@1 定义了:
 *      reg                     — 通道号 (1 = ADC_IN1)
 *      zephyr,gain             — 默认增益
 *      zephyr,reference        — 默认参考源
 *      zephyr,acquisition-time — 默认采样时间
 *      zephyr,resolution       — 默认分辨率
 *
 *    C 代码 adc_channel_setup() 时:
 *      驱动先读取 DTS 的默认值，然后用 adc_channel_cfg 中的值覆盖。
 *      如果 adc_channel_cfg 某字段未设置(值为 0)，则沿用 DTS 默认值。
 *
 *    所以 DTS 是"出厂默认值"，C 代码是"运行时覆盖"。
 *    两者都写是为了: DTS 让硬件配置可见 + C 代码显式控制。
 *    简单场景下只写 adc_channel_cfg 也能工作（驱动会用默认值填充）。
 */
&adc1 {
	#address-cells = <1>;
	#size-cells = <0>;

	pinctrl-0 = <&adc1_in1_pa1 &adc1_in2_pa2>;
	pinctrl-names = "default";
	st,adc-prescaler = <4>;
	dmas = <&dma2 0 0 (STM32_DMA_PERIPH_RX | STM32_DMA_16BITS) STM32_DMA_FIFO_FULL>;
	status = "okay";

	channel@1 {
		reg = <1>;
		zephyr,gain = "ADC_GAIN_1";
		zephyr,reference = "ADC_REF_INTERNAL";
		zephyr,acquisition-time = <ADC_ACQ_TIME_DEFAULT>;
		zephyr,resolution = <12>;
	};

	channel@2 {
		reg = <2>;
		zephyr,gain = "ADC_GAIN_1";
		zephyr,reference = "ADC_REF_INTERNAL";
		zephyr,acquisition-time = <ADC_ACQ_TIME_DEFAULT>;
		zephyr,resolution = <12>;
	};

	channel@16 {
		reg = <3>;
		zephyr,gain = "ADC_GAIN_1";
		zephyr,reference = "ADC_REF_INTERNAL";
		zephyr,acquisition-time = <ADC_ACQ_TIME_DEFAULT>;
		zephyr,resolution = <12>;
	};
};

&spi1 {
	status = "okay";
	pinctrl-0 = <&spi1_sck_pb3 &spi1_miso_pb4 &spi1_mosi_pb5>;
	pinctrl-names = "default";
	/* SPI1 外设时钟频率（APB2 经分频后的输入时钟） */
	clock-frequency = <16000000>;
	/*
	 * CS 片选 GPIO 列表：
	 *   子节点 reg=<0> 对应此列表的第 0 项，reg=<1> 对应第 1 项，以此类推
	 *   GPIO_ACTIVE_LOW 表示 CS 低电平有效（W25Q16 的 /CS 引脚）
	 *   如果硬件上 CS 直接连 GND（始终选中），jedec,spi-nor 驱动将无法正常工作，
	 *   因为驱动需要在每次 SPI 事务之间拉高 CS 来分隔命令帧
	 */
	cs-gpios = <&gpiob 0 GPIO_ACTIVE_LOW>;//是数组来的

	w25qxx: w25qxx@0 {
		compatible = "jedec,spi-nor";
		/* reg=<0> 对应 cs-gpios 列表第 0 项（PB0） */
		reg = <0>;
		/*
		 * SPI 最大时钟频率：
		 *   W25Q16 标准读模式最高 104 MHz，实际取 80 MHz 留余量
		 */
		spi-max-frequency = <80000000>;
		label = "W25Q16";
		/*
		 * JEDEC ID：[制造商 类型 容量]
		 *   ef = Winbond (华邦)
		 *   40 = 内存类型
		 *   15 = 16 Mbit 容量代码
		 * 驱动初始化时会读取芯片的 JEDEC ID 与此值比对校验
		 */
		jedec-id = [ef 40 15];
		/*
		 * Flash 容量，单位为 bit：
		 *   16777216 = 16 Mbit = 2 MB（W25Q16 的 "16" 指 16 Mbit）
		 */
		size = <16777216>;

		/*
		 * W25Q16 分区表（fixed-partitions）：
		 *   将 2MB Flash 划分为多个逻辑分区，每个分区可独立使用
		 *
		 * slot1_partition 在外部 flash 上的工作原理:
		 *   Zephyr flash_map 根据 DTS 自动为每个分区生成 flash_area 结构体，
		 *   fa_dev 字段通过 DT_MTD_FROM_PARTITION() 宏自动解析:
		 *     partition → fixed-partitions → w25qxx (jedec,spi-nor) → SPI NOR 驱动
		 *   因此 slot1 的 fa_dev 指向 W25Q16 的 SPI NOR 驱动，
		 *   MCUboot 通过 flash_area_read(slot1) 即可读取外部 flash 中的升级镜像。
		 *
		 */
		partitions {
			compatible = "fixed-partitions";
			#address-cells = <1>;
			#size-cells = <1>;

			lfs_partition: partition@0 {
				label = "lfs";
				reg = <0x00000000 0x00100000>; /* 前 1MB 给 LittleFS */
			};

			slot1_partition: partition@100000 {
				label = "image-1";
				reg = <0x00100000 0x00074000>; /* 464KB 给 MCUbot slot1 */
			};

			storage_partition: partition@174000 {
				label = "storage";
				reg = <0x00174000 0x0008c000>; /* 后 560KB 预留 */
			};
		};
	};
};

/*
 * 文件系统挂载表（fstab）：
 *   在 DTS 中声明文件系统挂载参数，构建系统自动生成 fs_mount_t 结构体
 *   应用代码通过 FS_FSTAB_DECLARE_ENTRY(DT_NODELABEL(lfs1)) 引用
 *
 * fstab 与传统手动 fs_mount() 的区别：
 *   - fstab：DTS 声明 → 自动生成结构体 → automount 自动挂载，代码零行
 *   - 手动：C 代码声明 fs_mount_t → 手动填充参数 → 手动调用 fs_mount()
 *   fstab 是 Zephyr 4.x 推荐方式，参数与硬件配置集中管理在 DTS 中
 */
/ {
	fstab {
		compatible = "zephyr,fstab";

		lfs1: lfs1 {
			compatible = "zephyr,fstab,littlefs";
			/* 挂载点路径：文件操作时使用此路径前缀，如 "/lfs1/config.txt" */
			mount-point = "/lfs1";
			/* 引用上面定义的 lfs_partition 分区 */
			partition = <&lfs_partition>;
			/*
			 * automount：启动时自动挂载
			 * 如果不设置，需要在应用代码中手动调用 fs_mount()
			 */
			automount;
			/*
			 * LittleFS 参数说明：
			 *   read-size      : 最小读取粒度（字节），建议 ≥ 16
			 *   prog-size      : 最小编程粒度（字节），建议 ≥ 16
			 *   cache-size     : 读/写缓存大小（字节），越大性能越好，但占用更多 RAM
			 *   lookahead-size : 前瞻缓冲区大小（字节），必须是 8 的倍数
			 *   block-cycles   : 磨损均衡擦除周期，0=禁用磨损均衡
			 *                    推荐 256~1024，值越大写入越快但磨损均衡越弱
			 *
			 * 这些参数影响 RAM 占用和性能，W25Q16 (2MB) 的推荐值：
			 *   RAM 占用 ≈ cache-size * 2 + lookahead-size ≈ 64*2+32 = 160 字节
			 */
			read-size = <16>;
			prog-size = <16>;
			cache-size = <64>;
			lookahead-size = <32>;
			block-cycles = <512>;
		};
	};
};
```

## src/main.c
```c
/*
 * Copyright (c) 2016 Intel Corporation
 *
 * SPDX-License-Identifier: Apache-2.0
 */

#include <stdio.h>
#include <inttypes.h>          // 提供 PRIu32 等格式化宏，用于跨平台打印 uint32_t
#include <string.h>
#include <zephyr/kernel.h>


#include "adc.h"
#include "uart.h"
#include "gpio-ctr.h"
#include "can_driver.h"
#include "modbus_driver.h"
#include "modbus_ser_a.h"
#include "modbus_cli_a.h"
#include "w25qxx.h"
#include "fs_storage.h"
#include "sys_param.h"
#include "iic_board.h"
#include "oled1306.h"

/* 初始化板级资源 */
static int board_init(void)
{
	int ret;
	ret = gpio_init_init();
	if (ret < 0) {
		printk("ERR: gpio init failed\n");
		return 1;
	}
	ret = adc_init();
	if (ret < 0) {
		printk("ERR: adc init failed\n");
		return 1;
	}

	/* 初始化文件系统（LittleFS 自动挂载检查） */
	ret = fs_storage_init();
	if (ret < 0) {
		printk("ERR: fs_storage init failed\n");
		return 1;
	}

	/* 运行文件系统读写测试 
	ret = fs_storage_test();
	if (ret < 0) {
		printk("ERR: fs_storage test failed\n");
	}
	*/

	/* 初始化参数系统（依赖 LittleFS 已挂载） */
	ret = sys_param_init();
	if (ret < 0) {
		printk("ERR: sys_param init failed\n");
		return 1;
	}

	/* 运行参数系统测试 
	ret = sys_param_test();
	if (ret < 0) {
		printk("ERR: sys_param test failed\n");
	}
	*/

	ret = can_drv_init_all();
	if (ret < 0) {
		printk("ERR: can_drv_init_all failed\n");
		return 1;
	}

	/* 串口初始化，已经用作modbus通信，这里注释掉
	ret = uart_init();
	if (ret < 0) {
		printk("ERR: uart init failed\n");
		return 1;
	}
	*/

	ret = modbus_ser_a_register();//注册服务器节点
	if (ret < 0) {
		printk("ERR: modbus_ser_a_register failed\n");
		return 1;
	}
	ret = modbus_cli_a_register();//注册客户端节点
	if (ret < 0) {
		printk("ERR: modbus_cli_a_register failed\n");
		return 1;
	}
	ret = modbus_drv_init_all();//初始化所有modbus驱动
	if (ret < 0) {
		printk("ERR: modbus_drv_init_all failed\n");
		return 1;
	}
	
	/* 初始化 W25Q16 SPI NOR Flash 已经用作文件系统，这里注释掉
	ret = w25qxx_init();
	if (ret < 0) {
		printk("ERR: w25qxx init failed\n");
		return 1;
	}
	/* w25qxx_test(); */
	
	/*
	 * 初始化 I2C1 总线
	 */
	ret = i2c_board_test();
	if (ret < 0) {
		printk("WARN: i2c board test failed (%d), continue...\n", ret);
	}

	/*
	 * OLED SSD1306 显示测试
	 */
	ret = oled_test();
	if (ret < 0) {
		printk("WARN: OLED test failed (%d), system continues "
		       "without display\n", ret);
	}

	/*
	 * 【重要】board_init() 必须显式 return 0。
	 *
	 * 在 ARM Cortex-M (GCC) 上，返回 int 的函数如果缺少 return 语句，
	 * R0 寄存器会残留上次函数调用的结果，导致 main() 收到一个随机的
	 * 返回值。例如当 oled_test() 返回 -19 (-ENODEV) 时，-19 会留在 R0
	 * 中被 main() 误判为 board_init() 失败，执行 return 1 使系统空闲。
	 */
	return 0;
}

/* ========================================================================== *
 * LED 控制线程                                                                *
 *                                                                            *
 * Zephyr 线程创建三要素：                                                     *
 *   1. 线程栈空间 — 必须通过 K_THREAD_STACK_DEFINE 宏静态分配，保证对齐要求    *
 *   2. 线程结构体 — struct k_thread，内核用于管理线程的内部对象                 *
 *   3. 线程入口函数 — 签名必须为 void func(void *p1, void *p2, void *p3)      *
 *                                                                            *
 * 线程优先级说明（数值越小优先级越高）：                                        *
 *   - 0 为最高优先级（仅限零延迟中断处理），一般应用不应使用                     *
 *   - 1~7 为协作式线程优先级，除非主动让出 CPU（k_yield/k_sleep），否则不会被打断 *
 *   - 8~14 为抢占式线程优先级，调度器会按优先级抢占调度                         *
 *   - 15 为最低优先级（idle 线程），一般不使用                                  *
 *   本线程优先级设为 5（协作式），LED 控制无需实时抢占，主动 sleep 让出 CPU 即可 *
 * ========================================================================== */

/* 线程栈大小（字节）
 * LED 控制逻辑简单，无大数组或深层调用栈，1024 字节足够
 * 可通过 k_thread_stack_space_get() 运行时查看剩余栈空间
 */
#define LED_THREAD_STACK_SIZE 1024
/* 线程优先级：5（协作式，不会抢占其他协作式线程） */
#define LED_THREAD_PRIORITY   5
/* 静态分配线程栈
 * K_THREAD_STACK_DEFINE 会处理 Zephyr 要求的栈对齐（通常 32 字节对齐）
 * 不能用普通数组代替，否则可能导致栈溢出或对齐异常
 */
K_THREAD_STACK_DEFINE(led_thread_stack, LED_THREAD_STACK_SIZE);
/* 线程结构体 — 内核通过此结构体管理线程状态、优先级、栈指针等 */
static struct k_thread led_thread_data;
/* 线程入口函数
 * Zephyr 线程入口函数固定签名为 void func(void *p1, void *p2, void *p3)
 * 三个 void* 参数通过 k_thread_create() 的 p1/p2/p3 传入
 * 本线程不需要参数，用 ARG_UNUSED 消除编译器未使用警告
 */
static void led_thread_entry(void *p1, void *p2, void *p3)
{
	ARG_UNUSED(p1);
	ARG_UNUSED(p2);
	ARG_UNUSED(p3);

	while (1) {
		led_ctr_ser();
		k_msleep(1); /* 休眠 1ms，主动让出 CPU，允许其他线程运行 */
	}
}

int main(void)
{
	int ret;
	static int cnt = 0;
	static int uart_cnt = 0;
	static uint8_t rec_can_flag = 0;
	char uart_msg[128];

	ret = board_init();
	if (ret < 0) {
		printk("ERR: board init failed\n");
		return 1;
	}

	
	modbus_cli_a_start();//启动客户端节点

	/* 启动 LED 控制线程
	 *
	 * k_thread_create 参数说明：
	 *   参数1 &led_thread_data  — 线程结构体指针，内核用此管理线程
	 *   参数2 led_thread_stack  — 线程栈起始地址（K_THREAD_STACK_DEFINE 分配）
	 *   参数3 K_THREAD_STACK_SIZEOF(led_thread_stack) — 栈大小
	 *          注意：必须用 K_THREAD_STACK_SIZEOF 宏而非 LED_THREAD_STACK_SIZE，
	 *          因为 K_THREAD_STACK_DEFINE 可能因对齐而多分配空间
	 *   参数4 led_thread_entry  — 线程入口函数
	 *   参数5/6/7 NULL, NULL, NULL — 传给入口函数的 p1/p2/p3 参数
	 *   参数8 LED_THREAD_PRIORITY — 线程优先级（5，协作式）
	 *   参数9 0 — 线程选项，0 表示无特殊选项
	 *          可选：K_ESSENTIAL（关键线程，异常时触发系统致命错误）
	 *                K_FP_REGS（使用浮点寄存器，STM32F4 的 FPU 需要此选项）
	 *                K_USER（用户模式线程，需启用 CONFIG_USERSPACE）
	 *   参数10 K_NO_WAIT — 延迟启动时间，K_NO_WAIT 表示立即调度运行
	 *          也可用 K_MSEC(x) 延迟 x 毫秒后再调度
	 */
	k_thread_create(&led_thread_data, led_thread_stack,
			K_THREAD_STACK_SIZEOF(led_thread_stack),
			led_thread_entry, NULL, NULL, NULL,
			LED_THREAD_PRIORITY, 0, K_NO_WAIT);

	/* 设置线程名称，配合 CONFIG_THREAD_NAME=y
	 * 在 GDB/OpenOCD 调试时可直接看到 "led_ctr" 而非线程编号
	 * 也可通过 k_thread_name_get() 在运行时获取线程名
	 */
	k_thread_name_set(&led_thread_data, "led_ctr");

	printk("=== Zephyr Hello World ===\n");
	printk("Board: %s\n", CONFIG_BOARD);

	while (1) {
        //
		int32_t val0_mv = 0, val1_mv = 0, temp_c = 0;
		cnt++;

		
		if(cnt % 1000 == 0)
		{
			/*
			 * ADC 读取 — 两种方式演示：
			 *
			 * 【当前使用】方式二（DMA 扫描模式）：
			 *   - 一次 adc_read 触发硬件扫描转换两个通道
			 *   - DMA 自动搬运数据，效率高
			 *   - 需要 CONFIG_ADC_STM32_DMA=y
			 *   - 需要 DTS 中配置 dmas 属性
			 *
			 * 【备选】方式一（中断逐通道模式）：
			 *   - 每次只读一个通道，分两次调用
			 *   - 不需要 DMA，纯中断即可
			 *   - 将下面 adc_read_all_scan 替换为：
			 *     ret  = adc_read_channel(1, &val0_mv);
			 *     ret |= adc_read_channel(2, &val1_mv);
			 */
			
			ret = adc_read_all_scan(&val0_mv, &val1_mv, &temp_c);
			if(ret < 0)
			{
				printk("ERR: adc read failed: %d\n", ret);
			}
			else
			{
				//printk("ADC ch1: %d mV, ch2: %d mV, temp: %d C\n",
				//       val0_mv, val1_mv, temp_c);
			}
		}

		if (cnt % 1000 == 0 || rec_can_flag) {
			struct can_frame frame = {0};
			frame.flags = CAN_FRAME_IDE;
			frame.id = 0x123;
			frame.dlc = 8;
			frame.data[0] = 0xF1;
			frame.data[1] = 0x22;
			frame.data[2] = 0x33;
			frame.data[3] = 0x44;
			frame.data[4] = 0x55;
			frame.data[5] = 0x66;
			frame.data[6] = 0x77;
			frame.data[7] = 0x88;
			//非阻塞发送帧 (K_NO_WAIT)
			can_drv_send(CAN_DEV_CAN1, &frame, K_NO_WAIT);
			rec_can_flag = 0;
		}

		//非阻塞检查是否有收到的帧 (K_NO_WAIT)
		struct can_frame frame;
		if (can_drv_recv(CAN_DEV_CAN1, &frame, K_NO_WAIT) == 0) {
			rec_can_flag = 1;
			printk("[CAN1] RX: ID=0x%08X, DLC=%d, Data=[%02X %02X %02X %02X %02X %02X %02X %02X]\n",
			       frame.id, frame.dlc, frame.data[0], frame.data[1], frame.data[2], frame.data[3], frame.data[4], frame.data[5], frame.data[6], frame.data[7]);
		}

		/* 串口测试，已经用作modbus通信，这里注释掉（二选一）
		if(cnt % 8 == 0)
		{
			uart_cnt++;
			sprintf(uart_msg, "Hello, UART!\t%d", uart_cnt);
			//uart3_tx_async((const uint8_t *)uart_msg, strlen(uart_msg));
		}
		//非阻塞检查是否有收到的帧 (K_NO_WAIT)
		//有数据就处理, 没有就继续跑主循环, 不阻塞
		struct uart_rx_frame rx_frame;
			while (uart4_rx_frame_get(&rx_frame, K_NO_WAIT) == 0) {
				printk("UART4: %.*s\n", (int)rx_frame.len, rx_frame.data);
			}
		*/
		

		/*
		uint64_t uptime_ms = k_uptime_get();// 获取系统运行时间（毫秒）
		k_sleep(K_MSEC(1));//休眠1ms
		K_MSEC() 宏将毫秒转换为内核时间单位
		k_sleep() 休眠，单位s
		k_sleep(K_SECONDS(1));休眠1s
		*/

		k_msleep(1);//休眠1ms
	}
	return 0;
}
```

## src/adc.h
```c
#ifndef __ADC_H__
#define __ADC_H__

#include <stdint.h>

int adc_init(void);

/*
 * 方式一（中断逐通道模式）: 每次只读 1 个通道
 *
 * 调用方式:
 *   int32_t val_mv;
 *   adc_read_channel(1, &val_mv);  // 读通道 1
 *   adc_read_channel(2, &val_mv);  // 读通道 2
 *   adc_read_channel(16, &val_mv); // 读通道 16 (温度传感器, 返回 mV)
 *
 * 特点: 不依赖 DMA，纯中断模式
 */
int adc_read_channel(uint8_t channel_id, int32_t *val_mv);

/*
 * 方式二（DMA 扫描模式）: 一次读取 3 个通道 (CH1 + CH2 + CH16)
 *
 * 调用方式:
 *   int32_t ch1_mv, ch2_mv, temp_c;
 *   adc_read_all_scan(&ch1_mv, &ch2_mv, &temp_c);
 *
 *   返回值:
 *     ch1_mv   — 通道 1 (PA1) 电压, 单位 mV
 *     ch2_mv   — 通道 2 (PA2) 电压, 单位 mV
 *     temp_c   — 芯片温度, 单位 °C
 *
 * 前提: CONFIG_ADC_STM32_DMA=y + DTS dmas + TSVREFE 已使能
 */
int adc_read_all_scan(int32_t *val0_mv, int32_t *val1_mv, int32_t *temp_celsius);

#endif
```

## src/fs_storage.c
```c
/*
 * 文件系统存储实现
 *
 * 本文件封装了 Zephyr VFS 文件操作 API，提供简洁的文件读写接口。
 * 底层使用 LittleFS 文件系统，通过 DTS fstab 机制自动挂载。
 *
 * 关键概念：
 *   - VFS（虚拟文件系统）：Zephyr 的统一文件操作层，fs_open/fs_read/fs_write 等
 *     API 不关心底层是 LittleFS 还是 FatFS，由 VFS 根据路径前缀自动路由
 *   - LittleFS：专为嵌入式设计的文件系统，掉电安全（不会损坏文件系统）、
 *     磨损均衡（自动分散写入位置延长 Flash 寿命）、极小 RAM 开销
 *   - fstab：DTS 中的文件系统挂载表，声明挂载参数后构建系统自动生成
 *     fs_mount_t 结构体，应用代码通过 FS_FSTAB_DECLARE_ENTRY 引用
 *   - automount：DTS 中设置后，LittleFS 在 SYS_INIT 阶段自动挂载，
 *     应用代码无需手动调用 fs_mount()
 *
 * 数据流（以 fs_write 为例）：
 *   fs_storage_write_file()
 *     → fs_open() / fs_write() / fs_close()        [VFS 层]
 *       → littlefs_write() → lfs_file_write()       [LittleFS 层]
 *         → lfs_api_prog() → flash_area_write()     [Flash Map 层]
 *           → spi_nor_write() → SPI 发送命令帧       [硬件驱动层]
 */

#include <zephyr/kernel.h>
#include <zephyr/fs/fs.h>             /* fs_open / fs_read / fs_write / fs_mount 等 VFS API */
#include <zephyr/fs/littlefs.h>       /* FS_FSTAB_DECLARE_ENTRY 宏 */
#include <zephyr/logging/log.h>
#include <string.h>
#include "fs_storage.h"

LOG_MODULE_REGISTER(fs_storage, LOG_LEVEL_INF);

/*
 * 通过 DTS fstab 声明 LittleFS 挂载点
 *
 * DT_NODELABEL(lfs1) 对应 DTS 中 lfs1: lfs1 { ... } 节点
 * FS_FSTAB_DECLARE_ENTRY 展开为：
 *   extern struct fs_mount_t z_fsmp_lfs1;
 * 即声明了由构建系统自动生成的 fs_mount_t 结构体
 *
 * 该结构体由 littlefs_fs.c 中的 DEFINE_FS 宏自动生成，包含：
 *   .type = FS_LITTLEFS
 *   .mnt_point = "/lfs1"
 *   .fs_data = &fs_data_lfs1（包含 read/prog/cache 缓冲区）
 *   .storage_dev = flash_area_id（指向 lfs_partition 分区）
 *   .flags = FS_MOUNT_FLAG_AUTOMOUNT（因为 DTS 中设置了 automount）
 */
#define LFS_PARTITION_NODE DT_NODELABEL(lfs1)
FS_FSTAB_DECLARE_ENTRY(LFS_PARTITION_NODE);

/*
 * 构建完整文件路径
 *
 * 如果 path 以 "/" 开头，视为绝对路径直接使用
 * 否则拼接挂载点前缀，如 "config.txt" → "/lfs1/config.txt"
 */
static int build_full_path(char *buf, size_t buf_size, const char *path)
{
	if (path[0] == '/') {
		/* 绝对路径，直接使用 */
		return snprintf(buf, buf_size, "%s", path);
	}
	/* 相对路径，拼接挂载点 */
	return snprintf(buf, buf_size, "%s/%s", FS_STORAGE_MOUNT_POINT, path);
}

int fs_storage_init(void)
{
	/*
	 * 获取 DTS fstab 自动生成的 fs_mount_t 结构体指针
	 *
	 * FS_FSTAB_ENTRY(LFS_PARTITION_NODE) 展开为 z_fsmp_lfs1
	 * 这是构建系统根据 DTS 中的 fstab 条目自动定义的全局变量
	 */
	struct fs_mount_t *mp = &FS_FSTAB_ENTRY(LFS_PARTITION_NODE);

	/*
	 * 检查文件系统是否已挂载
	 *
	 * 如果 DTS 中设置了 automount 且启用了 CONFIG_FS_LITTLEFS_FSTAB_AUTOMOUNT，
	 * LittleFS 会在 SYS_INIT 阶段（main() 之前）自动挂载
	 * 首次挂载时如果分区未格式化，LittleFS 会自动格式化后再挂载
	 */
	struct fs_statvfs stat;
	int rc = fs_statvfs(FS_STORAGE_MOUNT_POINT, &stat);
	if (rc == 0) {
		LOG_INF("LittleFS already mounted at %s", FS_STORAGE_MOUNT_POINT);
		LOG_INF("  Total: %lu bytes, Free: %lu bytes",
			(unsigned long)(stat.f_bsize * stat.f_blocks),
			(unsigned long)(stat.f_bsize * stat.f_bfree));
		return 0;
	}

	/*
	 * 如果自动挂载失败，尝试手动挂载
	 * 这通常发生在 automount 未启用或首次格式化失败时
	 */
	LOG_WRN("Auto-mount not detected, mounting manually...");
	rc = fs_mount(mp);
	if (rc != 0) {
		LOG_ERR("Manual mount failed: %d", rc);
		return rc;
	}

	LOG_INF("LittleFS mounted at %s", FS_STORAGE_MOUNT_POINT);
	return 0;
}

int fs_storage_write_file(const char *path, const uint8_t *data, size_t len)
{
	char full_path[64];
	struct fs_file_t file;
	int rc;

	/* 构建完整路径 */
	rc = build_full_path(full_path, sizeof(full_path), path);
	if (rc < 0 || (size_t)rc >= sizeof(full_path)) {
		LOG_ERR("Path too long: %s", path);
		return -EINVAL;
	}

	/*
	 * fs_file_t_init：初始化文件对象（必须在使用前调用）
	 * 类似于 C 标准库中 fopen 之前清零 FILE 结构体
	 */
	fs_file_t_init(&file);

	/*
	 * fs_open：打开文件
	 *   FS_O_CREATE : 文件不存在则创建
	 *   FS_O_WRITE  : 只写模式
	 *   FS_O_TRUNC  : 截断文件（清空已有内容后写入）
	 *
	 * 其他可用标志：
	 *   FS_O_READ   : 只读
	 *   FS_O_RDWR   : 读写
	 *   FS_O_APPEND : 追加模式（写入位置在文件末尾）
	 */
	rc = fs_open(&file, full_path, FS_O_CREATE | FS_O_WRITE | FS_O_TRUNC);
	if (rc < 0) {
		LOG_ERR("Failed to open %s for write: %d", full_path, rc);
		return rc;
	}

	/*
	 * fs_write：向文件写入数据
	 *   返回值：成功写入的字节数，负数表示错误
	 *   LittleFS 内部会自动处理：
	 *     - 写使能（WREN 命令）
	 *     - 按页编程（每页 256 字节，跨页自动分次）
	 *     - 等待写入完成（轮询状态寄存器 BUSY 位）
	 *     - 磨损均衡（block-cycles 决定换块频率）
	 */
	ssize_t written = fs_write(&file, data, len);
	if (written < 0) {
		LOG_ERR("Failed to write %s: %zd", full_path, written);
		fs_close(&file);
		return (int)written;
	}
	if ((size_t)written != len) {
		LOG_WRN("Partial write: %zu/%zu bytes", (size_t)written, len);
	}

	/* fs_close：关闭文件，刷新缓存到 Flash */
	fs_close(&file);

	LOG_INF("Written %zd bytes to %s", written, full_path);
	return 0;
}

int fs_storage_read_file(const char *path, uint8_t *buf, size_t buf_len,
			 size_t *out_len)
{
	char full_path[64];
	struct fs_file_t file;
	int rc;

	rc = build_full_path(full_path, sizeof(full_path), path);
	if (rc < 0 || (size_t)rc >= sizeof(full_path)) {
		LOG_ERR("Path too long: %s", path);
		return -EINVAL;
	}

	fs_file_t_init(&file);

	/* 以只读模式打开 */
	rc = fs_open(&file, full_path, FS_O_READ);
	if (rc < 0) {
		LOG_ERR("Failed to open %s for read: %d", full_path, rc);
		return rc;
	}

	/*
	 * fs_read：从文件读取数据
	 *   返回值：实际读取的字节数（可能小于 buf_len），0 表示文件末尾，负数表示错误
	 *   首次打开文件时，读取位置在文件开头（offset=0）
	 */
	ssize_t bytes_read = fs_read(&file, buf, buf_len);
	fs_close(&file);

	if (bytes_read < 0) {
		LOG_ERR("Failed to read %s: %zd", full_path, bytes_read);
		return (int)bytes_read;
	}

	if (out_len != NULL) {
		*out_len = (size_t)bytes_read;
	}

	LOG_INF("Read %zd bytes from %s", bytes_read, full_path);
	return 0;
}

int fs_storage_test(void)
{
	/*
	 * 测试场景：保存一个设备参数到文件，然后读回验证
	 *
	 * 这模拟了实际应用中最常见的场景：
	 *   - 设备首次启动，参数文件不存在 → 创建并写入默认值
	 *   - 设备后续启动，读取已保存的参数
	 *   - 参数变更时，覆盖写入新值
	 */
	const char *test_path = "param.txt";
	/* 测试参数：设备地址=1, 波特率=115200, 采样周期=1000ms */
	const char *test_param = "addr=1\nbaud=115200\nperiod=1000\n";
	size_t param_len = strlen(test_param);
	uint8_t read_buf[128];
	size_t read_len;
	int rc;

	LOG_INF("=== FS Storage Test Start ===");

	/* 步骤 1：写入参数文件 */
	LOG_INF("Step 1: Writing param file...");
	rc = fs_storage_write_file(test_path,
				   (const uint8_t *)test_param, param_len);
	if (rc != 0) {
		LOG_ERR("Write failed: %d", rc);
		return rc;
	}

	/* 步骤 2：读回参数文件 */
	LOG_INF("Step 2: Reading param file...");
	rc = fs_storage_read_file(test_path, read_buf, sizeof(read_buf) - 1,
				  &read_len);
	if (rc != 0) {
		LOG_ERR("Read failed: %d", rc);
		return rc;
	}

	/* 步骤 3：验证内容 */
	read_buf[read_len] = '\0'; /* 确保字符串以 null 结尾 */
	if (read_len == param_len &&
	    memcmp(test_param, read_buf, param_len) == 0) {
		LOG_INF("Step 3: Verify PASSED!");
		LOG_INF("Content:\n%s", read_buf);
	} else {
		LOG_ERR("Step 3: Verify FAILED!");
		LOG_ERR("Expected %zu bytes, got %zu bytes", param_len,
			read_len);
		return -EIO;
	}

	/* 步骤 4：列出目录内容 */
	LOG_INF("Step 4: Listing /lfs1/ directory...");
	struct fs_dir_t dir;
	struct fs_dirent entry;

	fs_dir_t_init(&dir);
	rc = fs_opendir(&dir, FS_STORAGE_MOUNT_POINT);
	if (rc != 0) {
		LOG_ERR("opendir failed: %d", rc);
		return rc;
	}

	while (fs_readdir(&dir, &entry) == 0 && entry.name[0] != '\0') {
		const char *type = (entry.type == FS_DIR_ENTRY_DIR)
					   ? "DIR "
					   : "FILE";
		LOG_INF("  [%s] %s (%zu bytes)", type, entry.name,
			(size_t)entry.size);
	}
	fs_closedir(&dir);

	LOG_INF("=== FS Storage Test Complete ===");
	return 0;
}
```

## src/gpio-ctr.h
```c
#ifndef __GPIO_CTRL_H__
#define __GPIO_CTRL_H__


int gpio_init_init(void);
void ledpin_toggle(uint8_t led);
void led_ctr_ser(void);



#endif
```

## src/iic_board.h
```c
#ifndef __IIC_BOARD_H__
#define __IIC_BOARD_H__

#include <stdint.h>

/*
 * I2C 初始化
 *
 * 获取设备树中定义的 I2C 总线设备句柄，并验证总线是否就绪。
 * 必须在使用任何 I2C 操作之前调用。
 *
 * 返回值: 0 成功, 被负的错误码失败
 */
int i2c_board_init(void);

/*
 * I2C 总线扫描
 *
 * 扫描 I2C 总线上所有可能的 7 位地址 (0x03 ~ 0x77)，
 * 打印检测到的设备地址。常用于硬件调试，确认设备连接正确。
 *
 * I2C 地址范围说明:
 *   0x00~0x02: 保留（广播/起始字节/CBUS）
 *   0x03~0x07: 保留
 *   0x08~0x77: 用户可用地址（共 112 个）
 *   0x78~0x7F: 10 位地址扩展保留
 *
 * 返回值: 扫描到的设备数量, 被负的错误码失败
 */
int i2c_board_scan(void);

/*
 * I2C 写寄存器（单字节寄存器地址 + 单字节数据）
 *
 * 这是 I2C 最常见的操作模式: 先发寄存器地址，再发数据。
 * 时序: [START] [设备地址+W] [寄存器地址] [数据] [STOP]
 *
 * 参数:
 *   dev_addr  — 7 位设备地址（不含 R/W 位）
 *   reg_addr  — 寄存器地址（1 字节）
 *   value     — 要写入的数据（1 字节）
 *
 * 返回值: 0 成功, 被负的错误码失败
 */
int i2c_board_write_reg(uint8_t dev_addr, uint8_t reg_addr, uint8_t value);

/*
 * I2C 读寄存器（单字节寄存器地址 + 单字节数据）
 *
 * 时序: [START] [设备地址+W] [寄存器地址]
 *       [RESTART] [设备地址+R] [读取数据] [STOP]
 *
 * 参数:
 *   dev_addr  — 7 位设备地址（不含 R/W 位）
 *   reg_addr  — 寄存器地址（1 字节）
 *   value     — 输出: 读取到的数据
 *
 * 返回值: 0 成功, 被负的错误码失败
 */
int i2c_board_read_reg(uint8_t dev_addr, uint8_t reg_addr, uint8_t *value);

/*
 * I2C 写多字节（寄存器地址 + 多字节数据）
 *
 * 常用于: 写 FIFO、批量配置寄存器、OLED 显存写入等。
 * 时序: [START] [设备地址+W] [寄存器地址] [数据0] [数据1] ... [STOP]
 *
 * 参数:
 *   dev_addr  — 7 位设备地址
 *   reg_addr  — 寄存器地址（1 字节）
 *   data      — 要写入的数据缓冲区
 *   len       — 数据长度（字节）
 *
 * 返回值: 0 成功, 被负的错误码失败
 */
int i2c_board_write_burst(uint8_t dev_addr, uint8_t reg_addr,
			  const uint8_t *data, uint16_t len);

/*
 * I2C 读多字节（寄存器地址 + 多字节数据）
 *
 * 常用于: 读 FIFO、批量读取传感器数据等。
 * 时序: [START] [设备地址+W] [寄存器地址]
 *       [RESTART] [设备地址+R] [数据0] [数据1] ... [STOP]
 *
 * 参数:
 *   dev_addr  — 7 位设备地址
 *   reg_addr  — 寄存器地址（1 字节）
 *   data      — 输出: 读取到的数据缓冲区
 *   len       — 要读取的字节数
 *
 * 返回值: 0 成功, 被负的错误码失败
 */
int i2c_board_read_burst(uint8_t dev_addr, uint8_t reg_addr,
			 uint8_t *data, uint16_t len);

/*
 * I2C 纯写（无寄存器地址，直接发数据）
 *
 * 常用于: OLED SSD1306 等设备的命令/数据写入（通过控制字节区分）。
 * 时序: [START] [设备地址+W] [数据0] [数据1] ... [STOP]
 *
 * 参数:
 *   dev_addr  — 7 位设备地址
 *   data      — 要发送的数据缓冲区
 *   len       — 数据长度（字节）
 *
 * 返回值: 0 成功, 被负的错误码失败
 */
int i2c_board_write_raw(uint8_t dev_addr, const uint8_t *data, uint16_t len);

/*
 * I2C 纯读（无寄存器地址，直接读数据）
 *
 * 常用于: 读取设备 ID、读取 FIFO 等无需指定寄存器地址的场景。
 * 时序: [START] [设备地址+R] [数据0] [数据1] ... [STOP]
 *
 * 参数:
 *   dev_addr  — 7 位设备地址
 *   data      — 输出: 读取到的数据缓冲区
 *   len       — 要读取的字节数
 *
 * 返回值: 0 成功, 被负的错误码失败
 */
int i2c_board_read_raw(uint8_t dev_addr, uint8_t *data, uint16_t len);

/*
 * I2C 综合测试
 *
 * 执行: 初始化 → 总线扫描 → 对 0x3C 设备尝试读取
 * 用于验证 I2C 硬件连接和驱动配置是否正确。
 *
 * 返回值: 0 成功, 被负的错误码失败
 */
int i2c_board_test(void);

#endif /* __IIC_BOARD_H__ */
```

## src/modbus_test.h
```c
#ifndef __MODBUS_TEST_H__
#define __MODBUS_TEST_H__

int init_modbus_test(void);
void set_modbus_temp(uint16_t temp);

#endif
```

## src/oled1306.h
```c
#ifndef __OLED1306_H__
#define __OLED1306_H__

/*
 * OLED SSD1306 显示驱动模块
 *
 * 基于 Zephyr Display 子系统 API，封装了常用的 OLED 操作:
 *   - 初始化与清屏
 *   - 逐像素绘制（点、线、矩形）
 *   - 帧缓冲区管理
 *   - 显示开关
 *
 * 注意: 本模块使用 Zephyr Display API（高层 API），
 *       与 iic_board.c 中的 I2C 底层 API 是不同的操作层级。
 *       两者不要同时操作同一个设备，否则会产生总线冲突。
 */

#include <stdint.h>
#include <stdbool.h>

/* 屏幕分辨率常量（与设备树中 width/height 对应） */
#define OLED_WIDTH   128
#define OLED_HEIGHT  64

/*
 * OLED 初始化
 *
 * 获取设备树中定义的 SSD1306 设备句柄，验证设备就绪，
 * 并清空屏幕内容。
 *
 * 返回值: 0 成功, 负的错误码失败
 */
int oled_init(void);

/*
 * 清空屏幕（所有像素关闭）
 *
 * 将帧缓冲区全部置零并刷新到屏幕。
 * SSD1306 像素格式 MONO01: 0 = 关闭, 1 = 点亮
 */
void oled_clear(void);

/*
 * 刷新屏幕
 *
 * 将当前帧缓冲区内容发送到 OLED 显示。
 * 所有绘制操作（set_pixel / draw_rect 等）只修改内存中的
 * 帧缓冲区，必须调用此函数才能在屏幕上看到变化。
 *
 * 典型用法:
 *   oled_clear();
 *   oled_draw_rect(0, 0, 128, 64, true);
 *   oled_refresh();   // 此时屏幕才更新
 *
 * 注意: display_write() 是同步阻塞调用，整屏刷新约需 ~25ms (400KHz I2C)
 */
void oled_refresh(void);

/*
 * 设置单个像素
 *
 * 参数:
 *   x     — 列坐标 (0 ~ OLED_WIDTH-1)
 *   y     — 行坐标 (0 ~ OLED_HEIGHT-1)
 *   on    — true=点亮, false=关闭
 */
void oled_set_pixel(uint16_t x, uint16_t y, bool on);

/*
 * 画水平线
 *
 * 参数:
 *   x     — 起始列
 *   y     — 行
 *   len   — 线长（像素数）
 *   on    — true=点亮, false=关闭
 */
void oled_draw_hline(uint16_t x, uint16_t y, uint16_t len, bool on);

/*
 * 画垂直线
 *
 * 参数:
 *   x     — 列
 *   y     — 起始行
 *   len   — 线长（像素数）
 *   on    — true=点亮, false=关闭
 */
void oled_draw_vline(uint16_t x, uint16_t y, uint16_t len, bool on);

/*
 * 画矩形边框
 *
 * 参数:
 *   x, y  — 左上角坐标
 *   w, h  — 宽度和高度
 *   on    — true=点亮, false=关闭
 */
void oled_draw_rect(uint16_t x, uint16_t y, uint16_t w, uint16_t h, bool on);

/*
 * 开关显示
 *
 * 参数:
 *   on — true=开启显示, false=关闭显示（省电模式）
 */
void oled_set_display(bool on);

/*
 * OLED 综合测试
 *
 * 执行: 初始化 → 清屏 → 显示测试图案和文字 → 等待 3 秒
 * 用于验证 OLED 硬件连接和驱动配置是否正确。
 *
 * 返回值: 0 成功, 负的错误码失败
 */
int oled_test(void);

#endif /* __OLED1306_H__ */
```
